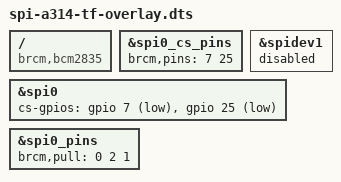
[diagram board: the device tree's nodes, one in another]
/dts-v1/;
/plugin/;

/ {
        compatible = "brcm,bcm2835";

        /*
          GPIO8 (normally SPI0-CE0) is used when the ICE40 is bus master, accessing the ROM.
          To not have conflicting pulls, we change the CE0 to use GPIO7 (normally SPI0-CE1) and CE1 to use GPIO25 instead (which isn't connected to anything).
          This way '/dev/spidev0,0' can still be used by a314d and we also disable `/dev/spidev0,1` as an extra precaution.
        */
        fragment@0 {
                target = <&spi0_cs_pins>;
                frag0: __overlay__ {
                        brcm,pins = <7 25>;
                };
        };

        fragment@1 {
                target = <&spidev1>;
                frag1: __overlay__ {
                        status = "disabled";
                };
        };

        fragment@2 {
                target = <&spi0>;
                frag2: __overlay__ {
                        cs-gpios = <&gpio 7 1>, <&gpio 25 1>;
                };
        };

        /*
          a314d keeps SCLK and MOSI as inputs between its transfers (the Pi drives them
          whenever they are in ALT0, against the TF4060's flash master):
          pull SCLK down to its idle level and MOSI up. spi0_pins: GPIO 9, 10, 11.
        */
        fragment@3 {
                target = <&spi0_pins>;
                frag3: __overlay__ {
                        brcm,pull = <0 2 1>;
                };
        };
};
